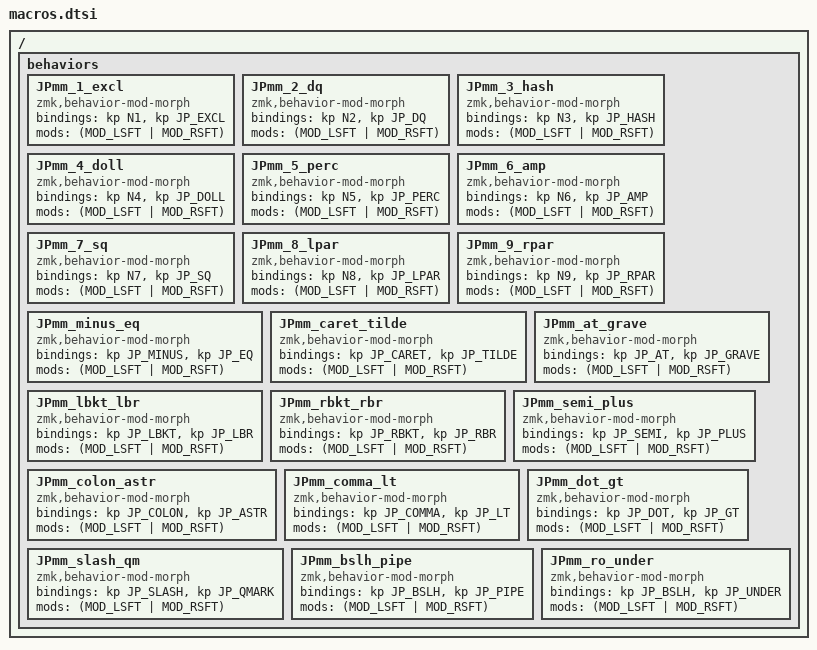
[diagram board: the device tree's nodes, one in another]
#include <dt-bindings/zmk/keys.h>
#include <dt-bindings/zmk/modifiers.h>


/* ===== JIS alias (ZMK safe) ===== */
/* --- 基本記号 --- */
#define JP_EXCL   EXCLAMATION   // !
#define JP_DQ     AT            // "  (Shift+2)
#define JP_HASH   HASH          // #
#define JP_DOLL   DOLLAR        // $
#define JP_PERC   PERCENT       // %
#define JP_AMP    CARET         // &  (Shift+6)
#define JP_SQ     AMPS          // '  (Shift+7)
#define JP_LPAR   STAR //ASTR          // (  (Shift+8)
#define JP_RPAR   LPAR          // )  (Shift+9)
#define JP_ASTR   DQT           // *  (「:*」キーの Shift)
#define JP_PLUS   COLON         // +  (「;+」キーの Shift)
#define JP_COMMA  COMMA         // ,
#define JP_MINUS  MINUS         // -
#define JP_DOT    DOT           // .
#define JP_SLASH  SLASH         // /

/* --- 数字系記号 --- */
#define JP_COLON  SQT //QUOTE         // :  (「:*」キーの通常)
#define JP_SEMI   SEMI          // ;
#define JP_LT     LT            // <
#define JP_EQ     UNDERSCORE    // =  (「-=」キーの Shift)
#define JP_GT     GT            // >
#define JP_QMARK  QMARK         // ?
#define JP_AT     LBKT          // @  (@キー)

/* --- 括弧・記号ブロック --- */
#define JP_LBKT   RBKT          // [  ([キー)
#define JP_BSLH   LBRC //INT1          // \  (ろキー) ※ZMK: International 1
#define JP_RBKT   BSLH          // ]  (]キー)
#define JP_CARET  EQUAL         // ^  (^~キーの通常)
#define JP_UNDER  LBRC //LS(INT1)      // _  (ろキーの Shift)
#define JP_GRAVE  LBRC          // `  (@キーの Shift)

/* --- シフト記号（JISでも使用） --- */
#define JP_LBR    RBRC          // {  ([キーの Shift)
#define JP_PIPE   LBRC //LS(INT3)      // |  (¥キーの Shift) ※ZMK: International 3
#define JP_RBR    PIPE          // }  (]キーの Shift)
#define JP_TILDE  PLUS          // ~  (^~キーの Shift)


/ {
    behaviors {

        /* ===== JIS symbol mod-morph ===== */

        // 1 !
        JPmm_1_excl: JPmm_1_excl {
            compatible = "zmk,behavior-mod-morph";
            #binding-cells = <0>;
            bindings = <&kp N1>, <&kp JP_EXCL>;
            mods = <(MOD_LSFT | MOD_RSFT)>;
        };

        // 2 "
        JPmm_2_dq: JPmm_2_dq {
            compatible = "zmk,behavior-mod-morph";
            #binding-cells = <0>;
            bindings = <&kp N2>, <&kp JP_DQ>;
            mods = <(MOD_LSFT | MOD_RSFT)>;
        };

        // 3 #
        JPmm_3_hash: JPmm_3_hash {
            compatible = "zmk,behavior-mod-morph";
            #binding-cells = <0>;
            bindings = <&kp N3>, <&kp JP_HASH>;
            mods = <(MOD_LSFT | MOD_RSFT)>;
        };

        // 4 $
        JPmm_4_doll: JPmm_4_doll {
            compatible = "zmk,behavior-mod-morph";
            #binding-cells = <0>;
            bindings = <&kp N4>, <&kp JP_DOLL>;
            mods = <(MOD_LSFT | MOD_RSFT)>;
        };

        // 5 %
        JPmm_5_perc: JPmm_5_perc {
            compatible = "zmk,behavior-mod-morph";
            #binding-cells = <0>;
            bindings = <&kp N5>, <&kp JP_PERC>;
            mods = <(MOD_LSFT | MOD_RSFT)>;
        };

        // 6 &
        JPmm_6_amp: JPmm_6_amp {
            compatible = "zmk,behavior-mod-morph";
            #binding-cells = <0>;
            bindings = <&kp N6>, <&kp JP_AMP>;
            mods = <(MOD_LSFT | MOD_RSFT)>;
        };

        // 7 '
        JPmm_7_sq: JPmm_7_sq {
            compatible = "zmk,behavior-mod-morph";
            #binding-cells = <0>;
            bindings = <&kp N7>, <&kp JP_SQ>;
            mods = <(MOD_LSFT | MOD_RSFT)>;
        };

        // 8 (
        JPmm_8_lpar: JPmm_8_lpar {
            compatible = "zmk,behavior-mod-morph";
            #binding-cells = <0>;
            bindings = <&kp N8>, <&kp JP_LPAR>;
            mods = <(MOD_LSFT | MOD_RSFT)>;
        };

        // 9 )
        JPmm_9_rpar: JPmm_9_rpar {
            compatible = "zmk,behavior-mod-morph";
            #binding-cells = <0>;
            bindings = <&kp N9>, <&kp JP_RPAR>;
            mods = <(MOD_LSFT | MOD_RSFT)>;
        };

        // - =
        JPmm_minus_eq: JPmm_minus_eq {
            compatible = "zmk,behavior-mod-morph";
            #binding-cells = <0>;
            bindings = <&kp JP_MINUS>, <&kp JP_EQ>;
            mods = <(MOD_LSFT | MOD_RSFT)>;
        };

        // ^ ~
        JPmm_caret_tilde: JPmm_caret_tilde {
            compatible = "zmk,behavior-mod-morph";
            #binding-cells = <0>;
            bindings = <&kp JP_CARET>, <&kp JP_TILDE>;
            mods = <(MOD_LSFT | MOD_RSFT)>;
        };

        // @ `
        JPmm_at_grave: JPmm_at_grave {
            compatible = "zmk,behavior-mod-morph";
            #binding-cells = <0>;
            bindings = <&kp JP_AT>, <&kp JP_GRAVE>;
            mods = <(MOD_LSFT | MOD_RSFT)>;
        };

        // [ {
        JPmm_lbkt_lbr: JPmm_lbkt_lbr {
            compatible = "zmk,behavior-mod-morph";
            #binding-cells = <0>;
            bindings = <&kp JP_LBKT>, <&kp JP_LBR>;
            mods = <(MOD_LSFT | MOD_RSFT)>;
        };

        // ] }
        JPmm_rbkt_rbr: JPmm_rbkt_rbr {
            compatible = "zmk,behavior-mod-morph";
            #binding-cells = <0>;
            bindings = <&kp JP_RBKT>, <&kp JP_RBR>;
            mods = <(MOD_LSFT | MOD_RSFT)>;
        };

        // ; +
        JPmm_semi_plus: JPmm_semi_plus {
            compatible = "zmk,behavior-mod-morph";
            #binding-cells = <0>;
            bindings = <&kp JP_SEMI>, <&kp JP_PLUS>;
            mods = <(MOD_LSFT | MOD_RSFT)>;
        };

        // : *
        JPmm_colon_astr: JPmm_colon_astr {
            compatible = "zmk,behavior-mod-morph";
            #binding-cells = <0>;
            bindings = <&kp JP_COLON>, <&kp JP_ASTR>;
            mods = <(MOD_LSFT | MOD_RSFT)>;
        };

        // , <
        JPmm_comma_lt: JPmm_comma_lt {
            compatible = "zmk,behavior-mod-morph";
            #binding-cells = <0>;
            bindings = <&kp JP_COMMA>, <&kp JP_LT>;
            mods = <(MOD_LSFT | MOD_RSFT)>;
        };

        // . >
        JPmm_dot_gt: JPmm_dot_gt {
            compatible = "zmk,behavior-mod-morph";
            #binding-cells = <0>;
            bindings = <&kp JP_DOT>, <&kp JP_GT>;
            mods = <(MOD_LSFT | MOD_RSFT)>;
        };

        // / ?
        JPmm_slash_qm: JPmm_slash_qm {
            compatible = "zmk,behavior-mod-morph";
            #binding-cells = <0>;
            bindings = <&kp JP_SLASH>, <&kp JP_QMARK>;
            mods = <(MOD_LSFT | MOD_RSFT)>;
        };

        // \ |
        JPmm_bslh_pipe: JPmm_bslh_pipe {
            compatible = "zmk,behavior-mod-morph";
            #binding-cells = <0>;
            bindings = <&kp JP_BSLH>, <&kp JP_PIPE>;
            mods = <(MOD_LSFT | MOD_RSFT)>;
        };

        // ろ \ _
        JPmm_ro_under: JPmm_ro_under {
            compatible = "zmk,behavior-mod-morph";
            #binding-cells = <0>;
            bindings = <&kp JP_BSLH>, <&kp JP_UNDER>;
            mods = <(MOD_LSFT | MOD_RSFT)>;
        };
    };
};
